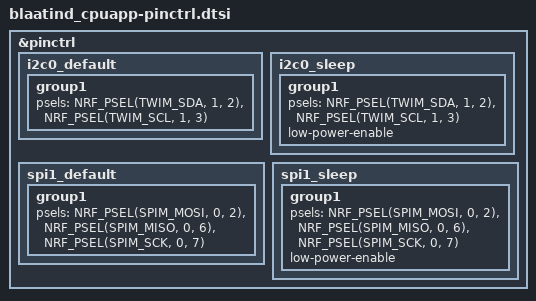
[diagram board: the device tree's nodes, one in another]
/*
 * Copyright (c) 2022 Nordic Semiconductor
 * SPDX-License-Identifier: Apache-2.0
 */

&pinctrl {
	i2c0_default: i2c0_default {
		group1 {
			psels = <NRF_PSEL(TWIM_SDA, 1, 2)>,
					<NRF_PSEL(TWIM_SCL, 1, 3)>;
		};
	};

	i2c0_sleep: i2c0_sleep {
		group1 {
			psels = <NRF_PSEL(TWIM_SDA, 1, 2)>,
					<NRF_PSEL(TWIM_SCL, 1, 3)>;
			low-power-enable;
		};
	};

	spi1_default: spi1_default {
		group1 {
			// Used for WS2812-style RGB strips, only MOSI needed
			psels = <NRF_PSEL(SPIM_MOSI, 0, 2)>,
					<NRF_PSEL(SPIM_MISO, 0, 6)>,
					<NRF_PSEL(SPIM_SCK,  0, 7)>;
		};
	};

	spi1_sleep: spi1_sleep {
		group1 {
			// Used for WS2812-style RGB strips, only MOSI needed
			psels = <NRF_PSEL(SPIM_MOSI, 0, 2)>,
					<NRF_PSEL(SPIM_MISO, 0, 6)>,
					<NRF_PSEL(SPIM_SCK,  0, 7)>;
			low-power-enable;
		};
	};

};
